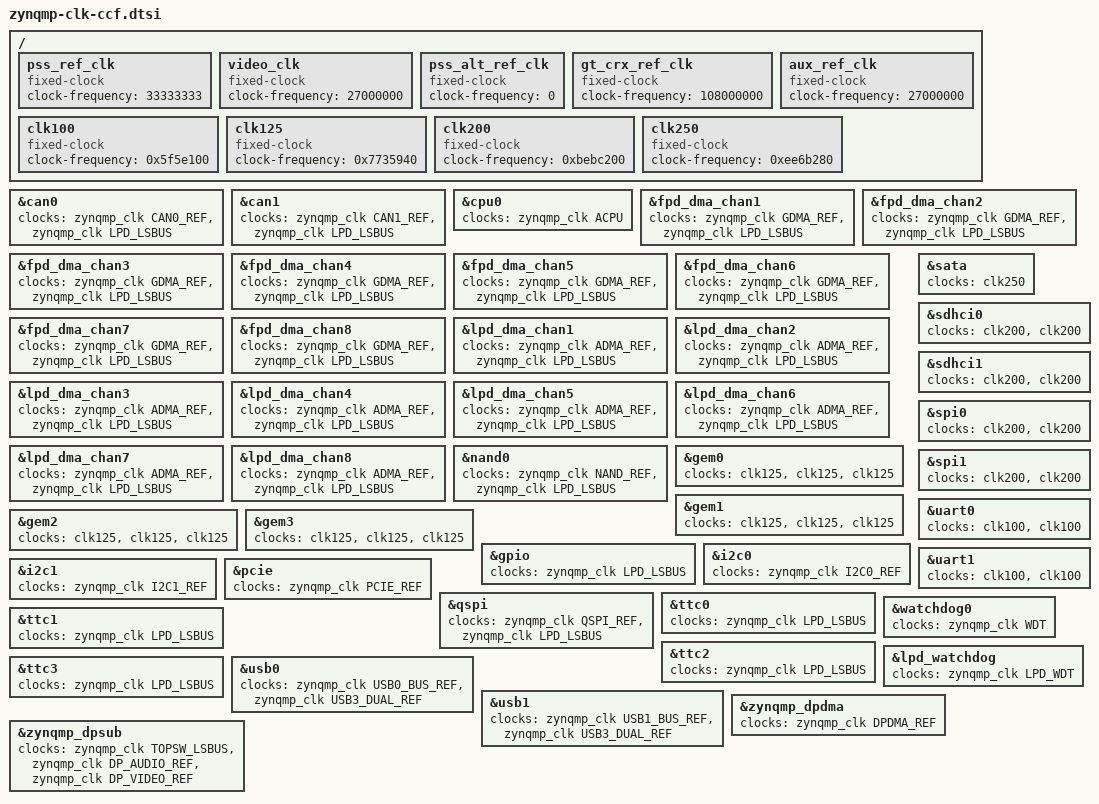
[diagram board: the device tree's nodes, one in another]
// SPDX-License-Identifier: GPL-2.0+
/*
 * Clock specification for Xilinx ZynqMP
 *
 * (C) Copyright 2017 - 2019, Xilinx, Inc.
 *
 * Michal Simek <michal.simek@xilinx.com>
 */

#include <dt-bindings/clock/xlnx-zynqmp-clk.h>
/ {
	pss_ref_clk: pss_ref_clk {
		compatible = "fixed-clock";
		#clock-cells = <0>;
		clock-frequency = <33333333>;
	};

	video_clk: video_clk {
		compatible = "fixed-clock";
		#clock-cells = <0>;
		clock-frequency = <27000000>;
	};

	pss_alt_ref_clk: pss_alt_ref_clk {
		compatible = "fixed-clock";
		#clock-cells = <0>;
		clock-frequency = <0>;
	};

	gt_crx_ref_clk: gt_crx_ref_clk {
		compatible = "fixed-clock";
		#clock-cells = <0>;
		clock-frequency = <108000000>;
	};

	aux_ref_clk: aux_ref_clk {
		compatible = "fixed-clock";
		#clock-cells = <0>;
		clock-frequency = <27000000>;
	};

        clk100: clk100 {
                compatible = "fixed-clock";
                #clock-cells = < 0x00 >;
                clock-frequency = < 0x5f5e100 >;
                phandle = < 0x05 >;
        };

        clk125: clk125 {
                compatible = "fixed-clock";
                #clock-cells = < 0x00 >;
                clock-frequency = < 0x7735940 >;
        };

        clk200: clk200 {
                compatible = "fixed-clock";
                #clock-cells = < 0x00 >;
                clock-frequency = < 0xbebc200 >;
        };

        clk250: clk250 {
                compatible = "fixed-clock";
                #clock-cells = < 0x00 >;
                clock-frequency = < 0xee6b280 >;
        };
};

&can0 {
	clocks = <&zynqmp_clk CAN0_REF>, <&zynqmp_clk LPD_LSBUS>;
};

&can1 {
	clocks = <&zynqmp_clk CAN1_REF>, <&zynqmp_clk LPD_LSBUS>;
};

&cpu0 {
	clocks = <&zynqmp_clk ACPU>;
};

&fpd_dma_chan1 {
	clocks = <&zynqmp_clk GDMA_REF>, <&zynqmp_clk LPD_LSBUS>;
};

&fpd_dma_chan2 {
	clocks = <&zynqmp_clk GDMA_REF>, <&zynqmp_clk LPD_LSBUS>;
};

&fpd_dma_chan3 {
	clocks = <&zynqmp_clk GDMA_REF>, <&zynqmp_clk LPD_LSBUS>;
};

&fpd_dma_chan4 {
	clocks = <&zynqmp_clk GDMA_REF>, <&zynqmp_clk LPD_LSBUS>;
};

&fpd_dma_chan5 {
	clocks = <&zynqmp_clk GDMA_REF>, <&zynqmp_clk LPD_LSBUS>;
};

&fpd_dma_chan6 {
	clocks = <&zynqmp_clk GDMA_REF>, <&zynqmp_clk LPD_LSBUS>;
};

&fpd_dma_chan7 {
	clocks = <&zynqmp_clk GDMA_REF>, <&zynqmp_clk LPD_LSBUS>;
};

&fpd_dma_chan8 {
	clocks = <&zynqmp_clk GDMA_REF>, <&zynqmp_clk LPD_LSBUS>;
};

&lpd_dma_chan1 {
	clocks = <&zynqmp_clk ADMA_REF>, <&zynqmp_clk LPD_LSBUS>;
};

&lpd_dma_chan2 {
	clocks = <&zynqmp_clk ADMA_REF>, <&zynqmp_clk LPD_LSBUS>;
};

&lpd_dma_chan3 {
	clocks = <&zynqmp_clk ADMA_REF>, <&zynqmp_clk LPD_LSBUS>;
};

&lpd_dma_chan4 {
	clocks = <&zynqmp_clk ADMA_REF>, <&zynqmp_clk LPD_LSBUS>;
};

&lpd_dma_chan5 {
	clocks = <&zynqmp_clk ADMA_REF>, <&zynqmp_clk LPD_LSBUS>;
};

&lpd_dma_chan6 {
	clocks = <&zynqmp_clk ADMA_REF>, <&zynqmp_clk LPD_LSBUS>;
};

&lpd_dma_chan7 {
	clocks = <&zynqmp_clk ADMA_REF>, <&zynqmp_clk LPD_LSBUS>;
};

&lpd_dma_chan8 {
	clocks = <&zynqmp_clk ADMA_REF>, <&zynqmp_clk LPD_LSBUS>;
};

&nand0 {
	clocks = <&zynqmp_clk NAND_REF>, <&zynqmp_clk LPD_LSBUS>;
};

&gem0 {
	clocks = <&clk125 &clk125 &clk125>;
	clock-names = "pclk", "hclk", "tx_clk";
};

&gem1 {
	clocks = <&clk125 &clk125 &clk125>;
	clock-names = "pclk", "hclk", "tx_clk";
};

&gem2 {
	clocks = <&clk125 &clk125 &clk125>;
	clock-names = "pclk", "hclk", "tx_clk";
};

&gem3 {
	clocks = <&clk125 &clk125 &clk125>;
	clock-names = "pclk", "hclk", "tx_clk";
};

&gpio {
	clocks = <&zynqmp_clk LPD_LSBUS>;
};

&i2c0 {
	clocks = <&zynqmp_clk I2C0_REF>;
};

&i2c1 {
	clocks = <&zynqmp_clk I2C1_REF>;
};

&pcie {
	clocks = <&zynqmp_clk PCIE_REF>;
};

&qspi {
	clocks = <&zynqmp_clk QSPI_REF>, <&zynqmp_clk LPD_LSBUS>;
};

&sata {
	clocks = <&clk250>;
};

&sdhci0 {
	clocks = <&clk200 &clk200>;
};

&sdhci1 {
	clocks = <&clk200 &clk200>;
};

&spi0 {
	clocks = <&clk200 &clk200>;
};

&spi1 {
	clocks = <&clk200 &clk200>;
};

&ttc0 {
	clocks = <&zynqmp_clk LPD_LSBUS>;
};

&ttc1 {
	clocks = <&zynqmp_clk LPD_LSBUS>;
};

&ttc2 {
	clocks = <&zynqmp_clk LPD_LSBUS>;
};

&ttc3 {
	clocks = <&zynqmp_clk LPD_LSBUS>;
};

&uart0 {
	clocks = <&clk100>, <&clk100>;
};

&uart1 {
	clocks = <&clk100>, <&clk100>;
};

&usb0 {
	clocks = <&zynqmp_clk USB0_BUS_REF>, <&zynqmp_clk USB3_DUAL_REF>;
};

&usb1 {
	clocks = <&zynqmp_clk USB1_BUS_REF>, <&zynqmp_clk USB3_DUAL_REF>;
};

&watchdog0 {
	clocks = <&zynqmp_clk WDT>;
};

&lpd_watchdog {
	clocks = <&zynqmp_clk LPD_WDT>;
};

&zynqmp_dpdma {
	clocks = <&zynqmp_clk DPDMA_REF>;
};

&zynqmp_dpsub {
	clocks = <&zynqmp_clk TOPSW_LSBUS>,
		 <&zynqmp_clk DP_AUDIO_REF>,
		 <&zynqmp_clk DP_VIDEO_REF>;
};
